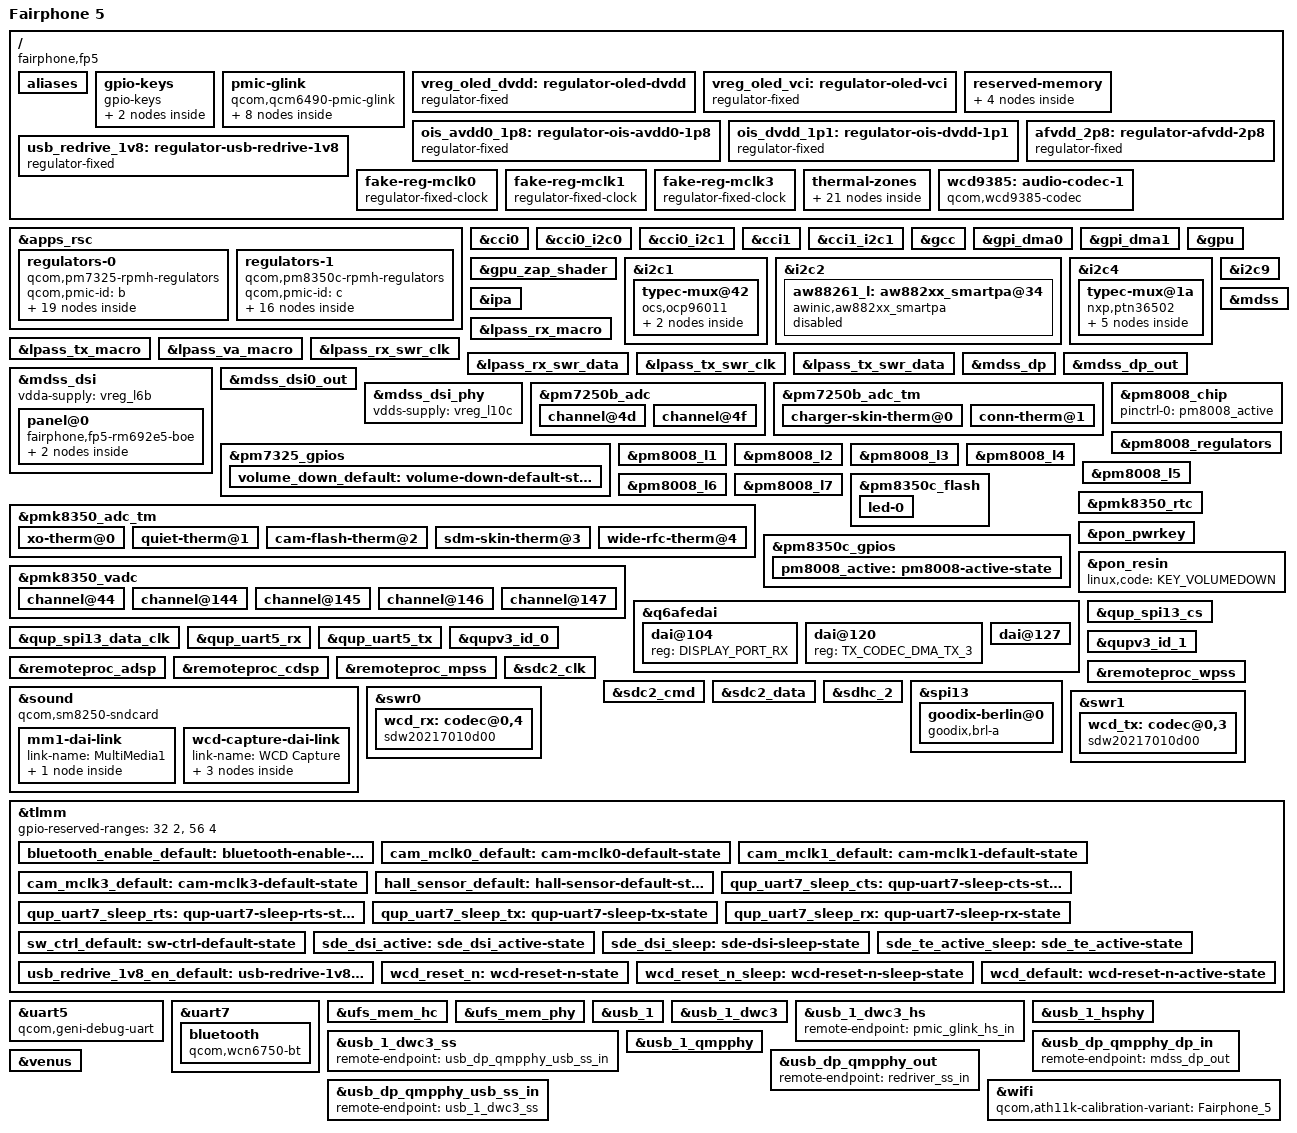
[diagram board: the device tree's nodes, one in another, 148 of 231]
// SPDX-License-Identifier: BSD-3-Clause
/*
 * Copyright (c) 2023, Luca Weiss <luca.weiss@fairphone.com>
 */

/dts-v1/;

/* PM7250B is configured to use SID8/9 */
#define PM7250B_SID 8
#define PM7250B_SID1 9

#include <dt-bindings/iio/qcom,spmi-adc7-pm7325.h>
#include <dt-bindings/iio/qcom,spmi-adc7-pmk8350.h>
#include <dt-bindings/leds/common.h>
#include <dt-bindings/pinctrl/qcom,pmic-gpio.h>
#include <dt-bindings/regulator/qcom,rpmh-regulator.h>
#include <dt-bindings/sound/qcom,q6afe.h>
#include <dt-bindings/sound/qcom,q6asm.h>
#include "sc7280.dtsi"
#include "pm7250b.dtsi"
#include "pm7325.dtsi"
#include "pm8350c.dtsi" /* PM7350C */
#include "pmk8350.dtsi" /* PMK7325 */

/delete-node/ &rmtfs_mem;

/ {
	model = "Fairphone 5";
	compatible = "fairphone,fp5", "qcom,qcm6490";
	chassis-type = "handset";

	aliases {
		serial0 = &uart5;
		serial1 = &uart7;
	};

	gpio-keys {
		compatible = "gpio-keys";

		pinctrl-0 = <&volume_down_default>, <&hall_sensor_default>;
		pinctrl-names = "default";

		key-volume-up {
			label = "Volume up";
			gpios = <&pm7325_gpios 6 GPIO_ACTIVE_LOW>;
			linux,code = <KEY_VOLUMEUP>;
		};

		/* Powered by the always-on vreg_l8c */
		event-hall-sensor {
			label = "Hall Effect Sensor";
			gpios = <&tlmm 155 GPIO_ACTIVE_LOW>;
			linux,input-type = <EV_SW>;
			linux,code = <SW_LID>;
			linux,can-disable;
			wakeup-source;
		};
	};

	pmic-glink {
		compatible = "qcom,qcm6490-pmic-glink", "qcom,pmic-glink";

		#address-cells = <1>;
		#size-cells = <0>;

		connector@0 {
			compatible = "usb-c-connector";
			reg = <0>;
			power-role = "dual";
			data-role = "dual";

			ports {
				#address-cells = <1>;
				#size-cells = <0>;

				port@0 {
					reg = <0>;

					pmic_glink_hs_in: endpoint {
						remote-endpoint = <&usb_1_dwc3_hs>;
					};
				};

				port@1 {
					reg = <1>;

					pmic_glink_ss_in: endpoint {
						remote-endpoint = <&redriver_ss_out>;
					};
				};

				port@2 {
					reg = <2>;

					pmic_glink_sbu: endpoint {
						remote-endpoint = <&ocp96011_sbu_mux>;
					};
				};
			};
		};
	};

	vreg_oled_dvdd: regulator-oled-dvdd {
		compatible = "regulator-fixed";
		regulator-name = "oled_dvdd";
		regulator-min-microvolt = <1200000>;
		regulator-max-microvolt = <1200000>;

		gpio = <&tlmm 51 GPIO_ACTIVE_HIGH>;
		enable-active-high;

		vin-supply = <&vreg_s1b>;

		regulator-boot-on;
	};

	vreg_oled_vci: regulator-oled-vci {
		compatible = "regulator-fixed";
		regulator-name = "oled_vci";
		regulator-min-microvolt = <3000000>;
		regulator-max-microvolt = <3000000>;

		gpio = <&pm8350c_gpios 7 GPIO_ACTIVE_HIGH>;
		enable-active-high;

		vin-supply = <&vreg_l13c>;

		regulator-boot-on;
	};

	reserved-memory {
		cont_splash_mem: cont-splash@e1000000 {
			reg = <0x0 0xe1000000 0x0 0x2300000>;
			no-map;
		};

		cdsp_mem: cdsp@88f00000 {
			reg = <0x0 0x88f00000 0x0 0x1e00000>;
			no-map;
		};

		removed_mem: removed@c0000000 {
			reg = <0x0 0xc0000000 0x0 0x5100000>;
			no-map;
		};

		rmtfs_mem: memory@f8500000 {
			compatible = "qcom,rmtfs-mem";
			reg = <0x0 0xf8500000 0x0 0x600000>;
			no-map;

			qcom,client-id = <1>;
			qcom,vmid = <QCOM_SCM_VMID_MSS_MSA>, <QCOM_SCM_VMID_NAV>;
		};
	};

	ois_avdd0_1p8: regulator-ois-avdd0-1p8 {
		compatible = "regulator-fixed";
		regulator-name = "OIS_AVDD0_1P8";
		regulator-min-microvolt = <1800000>;
		regulator-max-microvolt = <1800000>;
		gpio = <&tlmm 157 GPIO_ACTIVE_HIGH>;
		enable-active-high;
		vin-supply = <&vreg_bob>;
		regulator-always-on; // FIXME
	};

	ois_dvdd_1p1: regulator-ois-dvdd-1p1 {
		compatible = "regulator-fixed";
		regulator-name = "OIS_DVDD_1P1";
		regulator-min-microvolt = <1100000>;
		regulator-max-microvolt = <1100000>;
		gpio = <&tlmm 97 GPIO_ACTIVE_HIGH>;
		enable-active-high;
		vin-supply = <&vreg_s8b>;
		regulator-always-on; // FIXME
	};

	afvdd_2p8: regulator-afvdd-2p8 {
		compatible = "regulator-fixed";
		regulator-name = "AFVDD_2P8";
		regulator-min-microvolt = <2800000>;
		regulator-max-microvolt = <2800000>;
		gpio = <&tlmm 68 GPIO_ACTIVE_HIGH>;
		enable-active-high;
		vin-supply = <&vreg_bob>;
		regulator-always-on; // FIXME
	};

	usb_redrive_1v8: regulator-usb-redrive-1v8 {
		compatible = "regulator-fixed";
		regulator-name = "USB_REDRIVE_1V8";
		regulator-min-microvolt = <1800000>;
		regulator-max-microvolt = <1800000>;
		gpio = <&tlmm 61 GPIO_ACTIVE_HIGH>;
		enable-active-high;
		vin-supply = <&vreg_bob>;
		regulator-boot-on;

		pinctrl-0 = <&usb_redrive_1v8_en_default>;
		pinctrl-names = "default";
	};

	fake-reg-mclk0 {
		compatible = "regulator-fixed-clock";
		regulator-name = "fake-reg-mclk0";
		pinctrl-names = "default";
		pinctrl-0 = <&cam_mclk0_default>;
		clocks = <&camcc CAM_CC_MCLK0_CLK>;
		regulator-always-on;
	};

	fake-reg-mclk1 {
		compatible = "regulator-fixed-clock";
		regulator-name = "fake-reg-mclk1";
		pinctrl-names = "default";
		pinctrl-0 = <&cam_mclk1_default>;
		clocks = <&camcc CAM_CC_MCLK1_CLK>;
		regulator-always-on;
	};

	fake-reg-mclk3 {
		compatible = "regulator-fixed-clock";
		regulator-name = "fake-reg-mclk3";
		pinctrl-names = "default";
		pinctrl-0 = <&cam_mclk3_default>;
		clocks = <&camcc CAM_CC_MCLK3_CLK>;
		regulator-always-on;
	};

	thermal-zones {
		camera-thermal {
			polling-delay-passive = <0>;
			polling-delay = <0>;
			thermal-sensors = <&pmk8350_adc_tm 2>;

			trips {
				active-config0 {
					temperature = <125000>;
					hysteresis = <1000>;
					type = "passive";
				};
			};
		};

		chg-skin-thermal {
			polling-delay-passive = <0>;
			polling-delay = <0>;
			thermal-sensors = <&pm7250b_adc_tm 0>;

			trips {
				active-config0 {
					temperature = <125000>;
					hysteresis = <1000>;
					type = "passive";
				};
			};
		};

		conn-thermal {
			polling-delay-passive = <0>;
			polling-delay = <0>;
			thermal-sensors = <&pm7250b_adc_tm 1>;

			trips {
				active-config0 {
					temperature = <125000>;
					hysteresis = <1000>;
					type = "passive";
				};
			};
		};

		quiet-thermal {
			polling-delay-passive = <0>;
			polling-delay = <0>;
			thermal-sensors = <&pmk8350_adc_tm 1>;

			trips {
				active-config0 {
					temperature = <125000>;
					hysteresis = <1000>;
					type = "passive";
				};
			};
		};

		rear-cam-thermal {
			polling-delay-passive = <0>;
			polling-delay = <0>;
			thermal-sensors = <&pmk8350_adc_tm 4>;

			trips {
				active-config0 {
					temperature = <125000>;
					hysteresis = <1000>;
					type = "passive";
				};
			};
		};

		sdm-skin-thermal {
			polling-delay-passive = <0>;
			polling-delay = <0>;
			thermal-sensors = <&pmk8350_adc_tm 3>;

			trips {
				active-config0 {
					temperature = <125000>;
					hysteresis = <1000>;
					type = "passive";
				};
			};
		};

		xo-thermal {
			polling-delay-passive = <0>;
			polling-delay = <0>;
			thermal-sensors = <&pmk8350_adc_tm 0>;

			trips {
				active-config0 {
					temperature = <125000>;
					hysteresis = <1000>;
					type = "passive";
				};
			};
		};
	};

	wcd9385: audio-codec-1 {
		compatible = "qcom,wcd9385-codec";

		//pinctrl-0 = <&wcd_reset_n>;
		pinctrl-0 = <&wcd_default>;
		pinctrl-names = "default";
		//pinctrl-1 = <&wcd_reset_n_sleep>;
		//pinctrl-names = "default", "sleep";

		reset-gpios = <&tlmm 83 GPIO_ACTIVE_LOW>;

		qcom,rx-device = <&wcd_rx>;
		qcom,tx-device = <&wcd_tx>;

		vdd-rxtx-supply = <&vreg_l18b>;
		vdd-io-supply = <&vreg_l18b>; // ???
		vdd-buck-supply = <&vreg_l17b>;
		vdd-mic-bias-supply = <&vreg_bob>;

		qcom,micbias1-microvolt = <1800000>;
		qcom,micbias2-microvolt = <1800000>;
		qcom,micbias3-microvolt = <1800000>;
		qcom,micbias4-microvolt = <1800000>;

		// FIXME validate those
		qcom,mbhc-buttons-vthreshold-microvolt = <75000 150000 237000 500000 500000
							  500000 500000 500000>;
		qcom,mbhc-headset-vthreshold-microvolt = <1700000>;
		qcom,mbhc-headphone-vthreshold-microvolt = <50000>;
		#sound-dai-cells = <1>;
	};
};

&apps_rsc {
	regulators-0 {
		compatible = "qcom,pm7325-rpmh-regulators";
		qcom,pmic-id = "b";

		vreg_s1b: smps1 {
			regulator-min-microvolt = <1840000>;
			regulator-max-microvolt = <2040000>;
		};

		vreg_s7b: smps7 {
			regulator-min-microvolt = <535000>;
			regulator-max-microvolt = <1120000>;
		};

		vreg_s8b: smps8 {
			regulator-min-microvolt = <1200000>;
			regulator-max-microvolt = <1500000>;
			regulator-initial-mode = <RPMH_REGULATOR_MODE_RET>;
		};

		vreg_l1b: ldo1 {
			regulator-min-microvolt = <825000>;
			regulator-max-microvolt = <925000>;
			regulator-initial-mode = <RPMH_REGULATOR_MODE_HPM>;
		};

		vreg_l2b: ldo2 {
			regulator-min-microvolt = <2700000>;
			regulator-max-microvolt = <3544000>;
			regulator-initial-mode = <RPMH_REGULATOR_MODE_HPM>;
		};

		vreg_l3b: ldo3 {
			regulator-min-microvolt = <312000>;
			regulator-max-microvolt = <910000>;
			regulator-initial-mode = <RPMH_REGULATOR_MODE_HPM>;
		};

		vreg_l6b: ldo6 {
			regulator-min-microvolt = <1140000>;
			regulator-max-microvolt = <1260000>;
			regulator-initial-mode = <RPMH_REGULATOR_MODE_HPM>;
		};

		vreg_l7b: ldo7 {
			/* Constrained for UFS VCC, at least until UFS driver scales voltage */
			regulator-min-microvolt = <2952000>;
			regulator-max-microvolt = <2952000>;
			regulator-initial-mode = <RPMH_REGULATOR_MODE_HPM>;
		};

		vreg_l8b: ldo8 {
			regulator-min-microvolt = <870000>;
			regulator-max-microvolt = <970000>;
			regulator-initial-mode = <RPMH_REGULATOR_MODE_HPM>;
		};

		vreg_l9b: ldo9 {
			regulator-min-microvolt = <1200000>;
			regulator-max-microvolt = <1304000>;
			regulator-initial-mode = <RPMH_REGULATOR_MODE_HPM>;
		};

		vreg_l11b: ldo11 {
			regulator-min-microvolt = <1504000>;
			regulator-max-microvolt = <2000000>;
			regulator-initial-mode = <RPMH_REGULATOR_MODE_HPM>;
		};

		vreg_l12b: ldo12 {
			regulator-min-microvolt = <751000>;
			regulator-max-microvolt = <824000>;
			regulator-initial-mode = <RPMH_REGULATOR_MODE_HPM>;
		};

		vreg_l13b: ldo13 {
			regulator-min-microvolt = <530000>;
			regulator-max-microvolt = <824000>;
			regulator-initial-mode = <RPMH_REGULATOR_MODE_HPM>;
		};

		vreg_l14b: ldo14 {
			regulator-min-microvolt = <1080000>;
			regulator-max-microvolt = <1304000>;
			regulator-initial-mode = <RPMH_REGULATOR_MODE_HPM>;
		};

		vreg_l15b: ldo15 {
			regulator-min-microvolt = <765000>;
			regulator-max-microvolt = <1020000>;
			regulator-initial-mode = <RPMH_REGULATOR_MODE_HPM>;
		};

		vreg_l16b: ldo16 {
			regulator-min-microvolt = <1100000>;
			regulator-max-microvolt = <1300000>;
			regulator-initial-mode = <RPMH_REGULATOR_MODE_HPM>;
		};

		vreg_l17b: ldo17 {
			regulator-min-microvolt = <1700000>;
			regulator-max-microvolt = <1900000>;
			regulator-initial-mode = <RPMH_REGULATOR_MODE_HPM>;
		};

		vreg_l18b: ldo18 {
			regulator-min-microvolt = <1800000>;
			regulator-max-microvolt = <2000000>;
			regulator-initial-mode = <RPMH_REGULATOR_MODE_HPM>;
			regulator-always-on; // FIXME DVDD AW88261
		};

		vreg_l19b: ldo19 {
			regulator-min-microvolt = <1800000>;
			regulator-max-microvolt = <2000000>;
			regulator-initial-mode = <RPMH_REGULATOR_MODE_HPM>;
		};
	};

	regulators-1 {
		compatible = "qcom,pm8350c-rpmh-regulators";
		qcom,pmic-id = "c";

		vreg_s1c: smps1 {
			regulator-min-microvolt = <2190000>;
			regulator-max-microvolt = <2210000>;
			regulator-initial-mode = <RPMH_REGULATOR_MODE_HPM>;
		};

		vreg_s9c: smps9 {
			regulator-min-microvolt = <1010000>;
			regulator-max-microvolt = <1170000>;
			regulator-initial-mode = <RPMH_REGULATOR_MODE_HPM>;
		};

		vreg_l1c: ldo1 {
			regulator-min-microvolt = <1800000>;
			regulator-max-microvolt = <1980000>;
			regulator-initial-mode = <RPMH_REGULATOR_MODE_HPM>;
		};

		vreg_l2c: ldo2 {
			regulator-min-microvolt = <1800000>;
			regulator-max-microvolt = <1950000>;
			regulator-initial-mode = <RPMH_REGULATOR_MODE_HPM>;
		};

		vreg_l3c: ldo3 {
			regulator-min-microvolt = <3000000>;
			regulator-max-microvolt = <3400000>;
			regulator-initial-mode = <RPMH_REGULATOR_MODE_HPM>;
		};

		vreg_l4c: ldo4 {
			regulator-min-microvolt = <1620000>;
			regulator-max-microvolt = <3300000>;
			regulator-initial-mode = <RPMH_REGULATOR_MODE_HPM>;
		};

		vreg_l5c: ldo5 {
			regulator-min-microvolt = <1620000>;
			regulator-max-microvolt = <3300000>;
			regulator-initial-mode = <RPMH_REGULATOR_MODE_HPM>;
		};

		vreg_l6c: ldo6 {
			regulator-min-microvolt = <1650000>;
			regulator-max-microvolt = <3544000>;
			regulator-initial-mode = <RPMH_REGULATOR_MODE_HPM>;
		};

		vreg_l7c: ldo7 {
			regulator-min-microvolt = <3000000>;
			regulator-max-microvolt = <3544000>;
			regulator-initial-mode = <RPMH_REGULATOR_MODE_HPM>;
		};

		vreg_l8c: ldo8 {
			regulator-min-microvolt = <1620000>;
			regulator-max-microvolt = <2000000>;
			regulator-initial-mode = <RPMH_REGULATOR_MODE_HPM>;
			/* Hall sensor VDD */
			regulator-always-on;
		};

		vreg_l9c: ldo9 {
			regulator-min-microvolt = <2700000>;
			regulator-max-microvolt = <3544000>;
			regulator-initial-mode = <RPMH_REGULATOR_MODE_HPM>;
		};

		vreg_l10c: ldo10 {
			regulator-min-microvolt = <720000>;
			regulator-max-microvolt = <1050000>;
			regulator-initial-mode = <RPMH_REGULATOR_MODE_HPM>;
		};

		vreg_l11c: ldo11 {
			regulator-min-microvolt = <2800000>;
			regulator-max-microvolt = <3544000>;
			regulator-initial-mode = <RPMH_REGULATOR_MODE_HPM>;
		};

		vreg_l12c: ldo12 {
			regulator-min-microvolt = <1650000>;
			regulator-max-microvolt = <2000000>;
			regulator-initial-mode = <RPMH_REGULATOR_MODE_HPM>;
		};

		vreg_l13c: ldo13 {
			regulator-min-microvolt = <2700000>;
			regulator-max-microvolt = <3544000>;
			regulator-initial-mode = <RPMH_REGULATOR_MODE_HPM>;
		};

		vreg_bob: bob {
			regulator-min-microvolt = <3150000>;
			regulator-max-microvolt = <3960000>;
			regulator-initial-mode = <RPMH_REGULATOR_MODE_AUTO>;
		};
	};
};

&cci0 {
	status = "okay";
};

&cci0_i2c0 {
	/* IMX800 @ 1a */
};

&cci0_i2c1 {
	/* IMX858 @ 29 */
};

&cci1 {
	status = "okay";
};

&cci1_i2c1 {
	/* S5KJN1SQ03 @ 10 */
};

&gcc {
	protected-clocks = <GCC_CFG_NOC_LPASS_CLK>,
			   <GCC_EDP_CLKREF_EN>,
			   <GCC_MSS_CFG_AHB_CLK>,
			   <GCC_MSS_GPLL0_MAIN_DIV_CLK_SRC>,
			   <GCC_MSS_OFFLINE_AXI_CLK>,
			   <GCC_MSS_Q6SS_BOOT_CLK_SRC>,
			   <GCC_MSS_Q6_MEMNOC_AXI_CLK>,
			   <GCC_MSS_SNOC_AXI_CLK>,
			   <GCC_QSPI_CNOC_PERIPH_AHB_CLK>,
			   <GCC_QSPI_CORE_CLK>,
			   <GCC_QSPI_CORE_CLK_SRC>,
			   <GCC_SEC_CTRL_CLK_SRC>,
			   <GCC_WPSS_AHB_BDG_MST_CLK>,
			   <GCC_WPSS_AHB_CLK>,
			   <GCC_WPSS_RSCP_CLK>;
};

&gpi_dma0 {
	status = "okay";
};

&gpi_dma1 {
	status = "okay";
};

&gpu {
	status = "okay";
};

&gpu_zap_shader {
	firmware-name = "qcom/qcm6490/fairphone5/a660_zap.mdt";
};

&i2c1 {
	status = "okay";

	#include "pm8008.dtsi"

	typec-mux@42 {
		compatible = "ocs,ocp96011", "fcs,fsa4480";
		reg = <0x42>;

		interrupts-extended = <&tlmm 7 IRQ_TYPE_LEVEL_LOW>;

		vcc-supply = <&vreg_bob>;

		mode-switch;
		orientation-switch;

		port {
			ocp96011_sbu_mux: endpoint {
				remote-endpoint = <&pmic_glink_sbu>;
				data-lanes = <1 0>;
			};
		};
	};

	/* Pixelworks @ 26 */
	/* AW86927FCR haptics @ 5a */
};

&i2c2 {
	status = "okay";

#if 1
	aw88261_l: aw882xx_smartpa@34 {
		compatible = "awinic,aw882xx_smartpa";
		reg = <0x34>;
		irq-gpio = <&tlmm 63 0x2008>;
		/*dc-flag = <0>;*/
		/*sync-flag = <0>;*/
		sound-channel = <0>; /*0:pri_l 1:pri_r 2:sec_l 3:sec_r*/
		aw-tx-topo-id = <0x1000ff00>;
		aw-rx-topo-id = <0x1000ff01>;
		aw-tx-port-id = <0x1017>;
		aw-rx-port-id = <0x1016>;
		aw-re-min = <4000>;
		aw-re-max= <30000>;
		rename-flag = <1>;
		#sound-dai-cells = <0>;
		status = "disabled";
	};

#if 0
	aw882xx_smartpa@35 {
		compatible = "awinic,aw882xx_smartpa";
		reg = <0x35>;
		irq-gpio = <&tlmm 18 0x2008>;
		/*dc-flag = <0>;*/
		/*sync-flag = <0>;*/
		sound-channel = <1>; /*0:pri_l 1:pri_r 2:sec_l 3:sec_r*/
		aw-tx-topo-id = <0x1000ff00>;
		aw-rx-topo-id = <0x1000ff01>;
		aw-tx-port-id = <0x1017>;
		aw-rx-port-id = <0x1016>;
		aw-re-min = <4000>;
		aw-re-max= <30000>;
		rename-flag = <1>;
		status = "okay";
	};
#endif
#else
	aw88261_l: audio-codec@34 {
		compatible = "awinic,aw88261";
		reg = <0x34>;
		awinic,audio-channel = <0>;
		awinic,sync-flag;
		#sound-dai-cells = <0>;
	};

/*
[   18.186318] snd-sm8250 sound: control 2:0:0:PCM Playback Volume:0 is already present
[   18.186325] aw88261 2-0035: ASoC: Failed to add PCM Playback Volume: -16
[   18.186330] aw88261 2-0035: ASoC: error at snd_soc_component_probe on aw88261.2-0035: -16
[   18.186376] snd-sm8250 sound: ASoC: failed to instantiate card -16
[   18.186774] snd-sm8250: probe of sound failed with error -16
*/
#if 0
	aw88261_r: audio-codec@35 {
		compatible = "awinic,aw88261";
		reg = <0x35>;
		awinic,audio-channel = <1>;
		awinic,sync-flag;
		#sound-dai-cells = <0>;
	};
#endif
#endif
};

&i2c4 {
	status = "okay";

	typec-mux@1a {
		compatible = "nxp,ptn36502";
		reg = <0x1a>;

		vdd18-supply = <&usb_redrive_1v8>;

		retimer-switch;
		orientation-switch;

		ports {
			#address-cells = <1>;
			#size-cells = <0>;

			port@0 {
				reg = <0>;

				redriver_ss_out: endpoint {
					remote-endpoint = <&pmic_glink_ss_in>;
				};
			};

			port@1 {
				reg = <1>;

				redriver_ss_in: endpoint {
					remote-endpoint = <&usb_dp_qmpphy_out>;
				};
			};
		};
	};
};

&i2c9 {
	status = "okay";

	/* ST21NFC NFC @ 28 */
	/* VL53L3 ToF @ 29 */
};

&ipa {
	qcom,gsi-loader = "self";
	memory-region = <&ipa_fw_mem>;
	firmware-name = "qcom/qcm6490/fairphone5/ipa_fws.mdt";
	status = "okay";
};

&lpass_rx_macro {
	status = "okay";
};

&lpass_tx_macro {
	status = "okay";
};

&lpass_va_macro {
	status = "okay";
	//vdd-micb-supply = <&vreg_bob>; // FIXME? don't think this is set downstream, some code can be found but nothing in dt
};

&lpass_rx_swr_clk {
	drive-strength = <2>;
	slew-rate = <1>;
	bias-disable;
};

&lpass_rx_swr_data {
	drive-strength = <2>;
	slew-rate = <1>;
	bias-bus-hold;
};

&lpass_tx_swr_clk {
	drive-strength = <2>;
	slew-rate = <1>;
	bias-disable;
};

&lpass_tx_swr_data {
	drive-strength = <2>;
	slew-rate = <1>;
	bias-bus-hold;
};

&mdss {
	status = "okay";
};

&mdss_dp {
	status = "okay";
};

&mdss_dp_out {
	data-lanes = <0 1>;
	remote-endpoint = <&usb_dp_qmpphy_dp_in>;
};

&mdss_dsi {
	vdda-supply = <&vreg_l6b>;
	status = "okay";

	panel@0 {
		compatible = "fairphone,fp5-rm692e5-boe", "raydium,rm692e5";
		reg = <0>;

		reset-gpios = <&tlmm 44 GPIO_ACTIVE_LOW>;

		vci-supply = <&vreg_oled_vci>;
		vddio-supply = <&vreg_l12c>;
		dvdd-supply = <&vreg_oled_dvdd>;

		pinctrl-0 = <&sde_dsi_active &sde_te_active_sleep>;
		pinctrl-1 = <&sde_dsi_sleep &sde_te_active_sleep>;
		pinctrl-names = "default", "sleep";

		port {
			panel_in: endpoint {
				remote-endpoint = <&mdss_dsi0_out>;
			};
		};
	};
};

&mdss_dsi0_out {
	data-lanes = <0 1 2 3>;
	remote-endpoint = <&panel_in>;
};

&mdss_dsi_phy {
	vdds-supply = <&vreg_l10c>;
	status = "okay";
};

&pm7250b_adc {
	channel@4d {
		reg = <ADC5_AMUX_THM1_100K_PU>;
		qcom,ratiometric;
		qcom,hw-settle-time = <200>;
		qcom,pre-scaling = <1 1>;
		label = "charger_skin_therm";
	};

	channel@4f {
		reg = <ADC5_AMUX_THM3_100K_PU>;
		qcom,ratiometric;
		qcom,hw-settle-time = <200>;
		qcom,pre-scaling = <1 1>;
		label = "conn_therm";
	};
};

&pm7250b_adc_tm {
	status = "okay";

	charger-skin-therm@0 {
		reg = <0>;
		io-channels = <&pm7250b_adc ADC5_AMUX_THM1_100K_PU>;
		qcom,ratiometric;
		qcom,hw-settle-time-us = <200>;
	};

	conn-therm@1 {
		reg = <1>;
		io-channels = <&pm7250b_adc ADC5_AMUX_THM3_100K_PU>;
		qcom,ratiometric;
		qcom,hw-settle-time-us = <200>;
	};
};

&pm7325_gpios {
	volume_down_default: volume-down-default-state {
		pins = "gpio6";
		function = PMIC_GPIO_FUNC_NORMAL;
		power-source = <1>;
		bias-pull-up;
		input-enable;
	};
};

&pm8008_chip {
	pinctrl-names = "default";
	pinctrl-0 = <&pm8008_active>;
};

&pm8008_regulators {
	vdd_l1_l2-supply = <&vreg_s8b>;
	vdd_l3_l4-supply = <&vreg_bob>;
	vdd_l5-supply = <&vreg_bob>;
	vdd_l6-supply = <&vreg_s1b>;
	vdd_l7-supply = <&vreg_bob>;
};

&pm8008_l1 {
	regulator-min-microvolt = <1000000>;
	regulator-max-microvolt = <1200000>;
	regulator-min-dropout-voltage-microvolt = <160000>;
	regulator-always-on; // FIXME
};

&pm8008_l2 {
	regulator-min-microvolt = <950000>;
	/* Adjusted from downstream 1150000 to avoid regulator core failure
	   since current_uV on boot is 1.2V, but the regulator steps don't
	   include exactly 1.15V, just 1.152V */
	regulator-max-microvolt = <1152000>;
	regulator-min-dropout-voltage-microvolt = <128000>;
	regulator-always-on; // FIXME
};

&pm8008_l3 {
	regulator-min-microvolt = <2700000>;
	regulator-max-microvolt = <3000000>;
	regulator-min-dropout-voltage-microvolt = <144000>;
	regulator-always-on; // FIXME
};

&pm8008_l4 {
	regulator-min-microvolt = <2700000>;
	regulator-max-microvolt = <2900000>;
	regulator-min-dropout-voltage-microvolt = <128000>;
	regulator-always-on; // FIXME
};

&pm8008_l5 {
	/* Downstream min voltage: 2.7V. See comment at pm8008_l2 */
	regulator-min-microvolt = <2704000>;
	regulator-max-microvolt = <2900000>;
	regulator-min-dropout-voltage-microvolt = <128000>;
	regulator-always-on; // FIXME
};

&pm8008_l6 {
	regulator-min-microvolt = <1700000>;
	/* Downstream max voltage: 1.9V. See comment at pm8008_l2 */
	regulator-max-microvolt = <1904000>;
	regulator-min-dropout-voltage-microvolt = <136000>;
	regulator-always-on; // FIXME CCI pull-up regulator
};

&pm8008_l7 {
	regulator-min-microvolt = <2700000>;
	regulator-max-microvolt = <3000000>;
	regulator-min-dropout-voltage-microvolt = <312000>;
	regulator-always-on; // FIXME
};

&pm8350c_flash {
	status = "okay";

	led-0 {
		function = LED_FUNCTION_FLASH;
		color = <LED_COLOR_ID_WHITE>;
		led-sources = <1>, <4>;
		led-max-microamp = <500000>;
		flash-max-microamp = <1500000>;
		flash-max-timeout-us = <1280000>;
	};
};

&pmk8350_adc_tm {
	status = "okay";

	xo-therm@0 {
		reg = <0>;
		io-channels = <&pmk8350_vadc PMK8350_ADC7_AMUX_THM1_100K_PU>;
		qcom,ratiometric;
		qcom,hw-settle-time-us = <200>;
	};

	quiet-therm@1 {
		reg = <1>;
		io-channels = <&pmk8350_vadc PM7325_ADC7_AMUX_THM1_100K_PU>;
		qcom,ratiometric;
		qcom,hw-settle-time-us = <200>;
	};

	cam-flash-therm@2 {
		reg = <2>;
		io-channels = <&pmk8350_vadc PM7325_ADC7_AMUX_THM2_100K_PU>;
		qcom,ratiometric;
		qcom,hw-settle-time-us = <200>;
	};

	sdm-skin-therm@3 {
		reg = <3>;
		io-channels = <&pmk8350_vadc PM7325_ADC7_AMUX_THM3_100K_PU>;
		qcom,ratiometric;
		qcom,hw-settle-time-us = <200>;
	};

	wide-rfc-therm@4 {
		reg = <4>;
		io-channels = <&pmk8350_vadc PM7325_ADC7_AMUX_THM4_100K_PU>;
		qcom,ratiometric;
		qcom,hw-settle-time-us = <200>;
	};
};

&pm8350c_gpios {
	pm8008_active: pm8008-active-state {
		pins = "gpio3";
		function = PMIC_GPIO_FUNC_NORMAL;
		bias-disable;
		output-high;
	};
};

&pmk8350_rtc {
	status = "okay";
};

&pmk8350_vadc {
	status = "okay";

	channel@44 {
		reg = <PMK8350_ADC7_AMUX_THM1_100K_PU>;
		qcom,ratiometric;
		qcom,hw-settle-time = <200>;
		qcom,pre-scaling = <1 1>;
		label = "pmk8350_xo_therm";
	};

	channel@144 {
		reg = <PM7325_ADC7_AMUX_THM1_100K_PU>;
		qcom,ratiometric;
		qcom,hw-settle-time = <200>;
		qcom,pre-scaling = <1 1>;
		label = "pm7325_quiet_therm";
	};

	channel@145 {
		reg = <PM7325_ADC7_AMUX_THM2_100K_PU>;
		qcom,ratiometric;
		qcom,hw-settle-time = <200>;
		qcom,pre-scaling = <1 1>;
		label = "pm7325_cam_flash_therm";
	};

	channel@146 {
		reg = <PM7325_ADC7_AMUX_THM3_100K_PU>;
		qcom,ratiometric;
		qcom,hw-settle-time = <200>;
		qcom,pre-scaling = <1 1>;
		label = "pm7325_sdm_skin_therm";
	};

	channel@147 {
		reg = <PM7325_ADC7_AMUX_THM4_100K_PU>;
		qcom,ratiometric;
		qcom,hw-settle-time = <200>;
		qcom,pre-scaling = <1 1>;
		label = "pm7325_wide_rfc_therm";
	};
};

&pon_pwrkey {
	status = "okay";
};

&pon_resin {
	linux,code = <KEY_VOLUMEDOWN>;
	status = "okay";
};

&q6afedai {
	dai@104 {
		reg = <DISPLAY_PORT_RX>;
	};

	dai@120 {
		reg = <TX_CODEC_DMA_TX_3>;
	};

	// RX = playback?
	dai@127 {
		reg = <QUINARY_MI2S_RX>;
		// gpio152 is used (first data line of quinary i2s)
		qcom,sd-lines = <0>; // dai_mi2s4: qcom,msm-mi2s-rx-lines = <1>;
	};
};

&qup_spi13_cs {
	drive-strength = <6>;
	bias-disable;
};

&qup_spi13_data_clk {
	drive-strength = <6>;
	bias-disable;
};

&qup_uart5_rx {
	drive-strength = <2>;
	bias-disable;
};

&qup_uart5_tx {
	drive-strength = <2>;
	bias-disable;
};

&qupv3_id_0 {
	status = "okay";
};

&qupv3_id_1 {
	status = "okay";
};

&remoteproc_adsp {
	firmware-name = "qcom/qcm6490/fairphone5/adsp.mbn";
	status = "okay";
};

&remoteproc_cdsp {
	firmware-name = "qcom/qcm6490/fairphone5/cdsp.mbn";
	status = "okay";
};

&remoteproc_mpss {
	firmware-name = "qcom/qcm6490/fairphone5/modem.mbn";
	status = "okay";
};

&remoteproc_wpss {
	firmware-name = "qcom/qcm6490/fairphone5/wpss.mbn";
	status = "okay";
};

&sdc2_clk {
	drive-strength = <16>;
	bias-disable;
};

&sdc2_cmd {
	drive-strength = <10>;
	bias-pull-up;
};

&sdc2_data {
	drive-strength = <10>;
	bias-pull-up;
};

&sdhc_2 {
	vmmc-supply = <&vreg_l9c>;
	vqmmc-supply = <&vreg_l6c>;

	pinctrl-0 = <&sdc2_clk>, <&sdc2_cmd>, <&sdc2_data>;
	pinctrl-1 = <&sdc2_clk_sleep>, <&sdc2_cmd_sleep>, <&sdc2_data_sleep>;

	status = "okay";
};

&sound {
	compatible = "qcom,sm8250-sndcard"; // FIXME use qcom,sc7280-qdsp6-sndcard or so
	audio-routing =
		"AMIC1", "MIC BIAS1", // OK
		"AMIC2", "MIC BIAS2", // OK
		"AMIC3", "MIC BIAS1", // OK
		"AMIC4", "MIC BIAS3", // OK
		"TX SWR_INPUT0", "ADC1_OUTPUT", // from https://lore.kernel.org/linux-arm-msm/20240124164505.293202-3-krzysztof.kozlowski@linaro.org/
		"TX SWR_INPUT1", "ADC2_OUTPUT",
		"TX SWR_INPUT0", "ADC3_OUTPUT",
		"TX SWR_INPUT1", "ADC4_OUTPUT",
		"TX SWR_ADC0", "ADC1_OUTPUT", // ?
		"TX SWR_ADC1", "ADC2_OUTPUT", // ?
		"TX SWR_ADC2", "ADC3_OUTPUT", // ?
		"TX SWR_ADC3", "ADC4_OUTPUT"; // ?
	pinctrl-0 = <&i2s1_active>;
	pinctrl-names = "default";
	model = "Fairphone 5";

	// FIXME seems to be enabled downstream but since we don't use WSA macro, probably not used
	assigned-clocks = <&q6afecc LPASS_CLK_ID_WSA_CORE_MCLK LPASS_CLK_ATTRIBUTE_COUPLE_NO>,
			  <&q6afecc LPASS_CLK_ID_WSA_CORE_NPL_MCLK LPASS_CLK_ATTRIBUTE_COUPLE_NO>;
	assigned-clock-rates = <19200000>, <19200000>;

	mm1-dai-link {
		link-name = "MultiMedia1";
		cpu {
			sound-dai = <&q6asmdai MSM_FRONTEND_DAI_MULTIMEDIA1>;
		};
	};

#if 0
	i2s-dai-link {
		link-name = "I2S Playback";
		cpu {
			// From my understanding, the playback path to the amplifier is via GPIO152 / QUINARY_MI2S_RX.
			// The amplifier also returns the audio (I2STXEN) via GPIO153 / QUINARY_MI2S_TX for echo-reference.
			sound-dai = <&q6afedai QUINARY_MI2S_RX>;
		};

		platform {
			sound-dai = <&q6routing>;
		};

		codec {
			sound-dai = <&aw88261_l>; // , <&aw88261_r>;
		};
	};
#endif

	wcd-capture-dai-link {
		link-name = "WCD Capture";

		cpu {
			sound-dai = <&q6afedai TX_CODEC_DMA_TX_3>;
		};

		platform {
			sound-dai = <&q6routing>;
		};

		codec {
			sound-dai = <&wcd9385 1>, <&swr1 0>, <&lpass_tx_macro 0>;
		};
	};

#if 0
	displayport-rx-dai-link {
		link-name = "DisplayPort Playback";

		cpu {
			sound-dai = <&q6afedai DISPLAY_PORT_RX>;
		};

		platform {
			sound-dai = <&q6routing>;
		};

		codec {
			sound-dai = <&mdss_dp>;
		};
	};
#endif
};

&spi13 {
	status = "okay";

	/* Goodix touchscreen @ 0 */
	goodix-berlin@0 {
		compatible = "goodix,brl-a";
		reg = <0>;
		spi-max-frequency = <1000000>;

		goodix,avdd-name = "avdd"; //3.0v
		avdd-supply = <&vreg_l3c>;
		goodix,iovdd-name = "iovdd"; //1.8v
		iovdd-supply = <&vreg_l2c>;

		goodix,irq-gpio = <&tlmm 81 0x0>;
		goodix,irq-flags = <1>; // 1:trigger rising, 2:trigger falling;
		goodix,reset-gpio = <&tlmm 105 0x0>;

		goodix,panel-max-x = <1224>;
		goodix,panel-max-y = <2700>;
		goodix,panel-max-w = <255>;

		//panel = <&rm692e5_boe_amoled_cmd>;

		goodix.sleep-enable; // enter sleep mode
		goodix,firmware-name = "GT9897_05.01.FF.17_4D6C5476.bin";
		goodix,config-name = "goodix_cfg_group_V14.bin";
	};
};

&swr0 {
	status = "okay";

	wcd_rx: codec@0,4 {
		compatible = "sdw20217010d00";
		reg = <0 4>;
		qcom,rx-port-mapping = <1 2 3 4 5>;
	};
};

&swr1 {
	status = "okay";

	wcd_tx: codec@0,3 {
		compatible = "sdw20217010d00";
		reg = <0 3>;
		qcom,tx-port-mapping = <2 2 3 4>;
	};
};

&tlmm {
	/*
	 * 32-33: SMB1394 (SPMI)
	 * 56-59: fingerprint reader (SPI)
	 */
	gpio-reserved-ranges = <32 2>, <56 4>;

	bluetooth_enable_default: bluetooth-enable-default-state {
		pins = "gpio85";
		function = "gpio";
		output-low;
		bias-disable;
	};

	cam_mclk0_default: cam-mclk0-default-state {
		pins = "gpio64";
		function = "cam_mclk";
		drive-strength = <2>;
		bias-disable;
	};

	cam_mclk1_default: cam-mclk1-default-state {
		pins = "gpio65";
		function = "cam_mclk";
		drive-strength = <2>;
		bias-disable;
	};

	cam_mclk3_default: cam-mclk3-default-state {
		pins = "gpio67";
		function = "cam_mclk";
		drive-strength = <2>;
		bias-disable;
	};

	hall_sensor_default: hall-sensor-default-state {
		pins = "gpio155";
		function = "gpio";
		drive-strength = <2>;
		bias-pull-up;
	};

	qup_uart7_sleep_cts: qup-uart7-sleep-cts-state {
		pins = "gpio28";
		function = "gpio";
		/*
		 * Configure a bias-bus-hold on CTS to lower power
		 * usage when Bluetooth is turned off. Bus hold will
		 * maintain a low power state regardless of whether
		 * the Bluetooth module drives the pin in either
		 * direction or leaves the pin fully unpowered.
		 */
		bias-bus-hold;
	};

	qup_uart7_sleep_rts: qup-uart7-sleep-rts-state {
		pins = "gpio29";
		function = "gpio";
		/*
		 * Configure pull-down on RTS. As RTS is active low
		 * signal, pull it low to indicate the BT SoC that it
		 * can wakeup the system anytime from suspend state by
		 * pulling RX low (by sending wakeup bytes).
		 */
		bias-pull-down;
	};

	qup_uart7_sleep_tx: qup-uart7-sleep-tx-state {
		pins = "gpio30";
		function = "gpio";
		/*
		 * Configure pull-up on TX when it isn't actively driven
		 * to prevent BT SoC from receiving garbage during sleep.
		 */
		bias-pull-up;
	};

	qup_uart7_sleep_rx: qup-uart7-sleep-rx-state {
		pins = "gpio31";
		function = "gpio";
		/*
		 * Configure a pull-up on RX. This is needed to avoid
		 * garbage data when the TX pin of the Bluetooth module
		 * is floating which may cause spurious wakeups.
		 */
		bias-pull-up;
	};

	sw_ctrl_default: sw-ctrl-default-state {
		pins = "gpio86";
		function = "gpio";
		bias-pull-down;
	};

	sde_dsi_active: sde_dsi_active-state {
		pins = "gpio44";
		function = "gpio";
		drive-strength = <8>;
		bias-disable;
	};

	sde_dsi_sleep: sde-dsi-sleep-state {
		pins = "gpio44";
		function = "gpio";
		drive-strength = <2>;
		bias-pull-down;
	};

	sde_te_active_sleep: sde_te_active-state {
		pins = "gpio80";
		function = "mdp_vsync";
		drive-strength = <2>;
		bias-pull-down;
	};

	usb_redrive_1v8_en_default: usb-redrive-1v8-en-default-state {
		pins = "gpio61";
		function = "gpio";
		drive-strength = <2>;
		bias-disable;
		output-high;
	};

	wcd_reset_n: wcd-reset-n-state {
		pins = "gpio83";
		function = "gpio";
		drive-strength = <16>;
	};

	wcd_reset_n_sleep: wcd-reset-n-sleep-state {
		pins = "gpio83";
		function = "gpio";
		drive-strength = <16>;
		bias-disable;
	};

	wcd_default: wcd-reset-n-active-state {
		pins = "gpio83";
		function = "gpio";
		drive-strength = <16>;
		bias-disable;
		output-low;
	};
};

&uart5 {
	compatible = "qcom,geni-debug-uart";
	status = "okay";
};

&uart7 {
	/delete-property/interrupts;
	interrupts-extended = <&intc GIC_SPI 608 IRQ_TYPE_LEVEL_HIGH>,
			      <&tlmm 31 IRQ_TYPE_EDGE_FALLING>;

	pinctrl-1 = <&qup_uart7_sleep_cts>, <&qup_uart7_sleep_rts>, <&qup_uart7_sleep_tx>, <&qup_uart7_sleep_rx>;
	pinctrl-names = "default", "sleep";

	status = "okay";

	bluetooth: bluetooth {
		compatible = "qcom,wcn6750-bt";

		pinctrl-0 = <&bluetooth_enable_default>, <&sw_ctrl_default>;
		pinctrl-names = "default";

		enable-gpios = <&tlmm 85 GPIO_ACTIVE_HIGH>;
		swctrl-gpios = <&tlmm 86 GPIO_ACTIVE_HIGH>;

		vddio-supply = <&vreg_l19b>;
		vddaon-supply = <&vreg_s7b>;
		vddbtcxmx-supply = <&vreg_s7b>;
		vddrfacmn-supply = <&vreg_s7b>;
		vddrfa0p8-supply = <&vreg_s7b>;
		vddrfa1p7-supply = <&vreg_s1b>;
		vddrfa1p2-supply = <&vreg_s8b>;
		vddrfa2p2-supply = <&vreg_s1c>;
		vddasd-supply = <&vreg_l11c>;

		max-speed = <3200000>;
	};
};

&ufs_mem_hc {
	reset-gpios = <&tlmm 175 GPIO_ACTIVE_LOW>;

	vcc-supply = <&vreg_l7b>;
	vcc-max-microamp = <800000>;
	/*
	 * Technically l9b enables an eLDO (supplied by s1b) which then powers
	 * VCCQ2 of the UFS.
	 */
	vccq-supply = <&vreg_l9b>;
	vccq-max-microamp = <900000>;

	status = "okay";
};

&ufs_mem_phy {
	vdda-phy-supply = <&vreg_l10c>;
	vdda-pll-supply = <&vreg_l6b>;

	status = "okay";
};

&usb_1 {
	status = "okay";
};

&usb_1_dwc3 {
	dr_mode = "otg";
	usb-role-switch;
};

&usb_1_dwc3_hs {
	remote-endpoint = <&pmic_glink_hs_in>;
};

&usb_1_dwc3_ss {
	remote-endpoint = <&usb_dp_qmpphy_usb_ss_in>;
};

&usb_1_hsphy {
	vdda-pll-supply = <&vreg_l10c>;
	vdda18-supply = <&vreg_l1c>;
	vdda33-supply = <&vreg_l2b>;

	qcom,hs-crossover-voltage-microvolt = <28000>;
	qcom,hs-output-impedance-micro-ohms = <2600000>;
	qcom,hs-rise-fall-time-bp = <5430>;
	qcom,hs-disconnect-bp = <1743>;
	qcom,hs-amplitude-bp = <2430>;

	qcom,pre-emphasis-amplitude-bp = <20000>;
	qcom,pre-emphasis-duration-bp = <20000>;

	qcom,squelch-detector-bp = <(-2090)>;

	status = "okay";
};

&usb_1_qmpphy {
	vdda-phy-supply = <&vreg_l6b>;
	vdda-pll-supply = <&vreg_l1b>;

	orientation-switch;

	status = "okay";
};

&usb_dp_qmpphy_dp_in {
	remote-endpoint = <&mdss_dp_out>;
};

&usb_dp_qmpphy_out {
	remote-endpoint = <&redriver_ss_in>;
};

&usb_dp_qmpphy_usb_ss_in {
	remote-endpoint = <&usb_1_dwc3_ss>;
};

&venus {
	firmware-name = "qcom/qcm6490/fairphone5/venus.mbn";
	status = "okay";
};

&wifi {
	qcom,ath11k-calibration-variant = "Fairphone_5";
	status = "okay";
};
